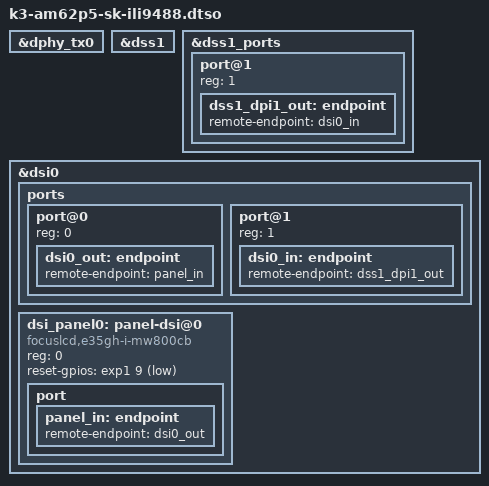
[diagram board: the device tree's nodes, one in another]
// SPDX-License-Identifier: GPL-2.0-or-later OR MIT
/**
 * Focus LCD MIPI DSI panel E35GH-I-MW800-CB
 *
 * AM62P5-SK EVM: https://www.ti.com/tool/SK-AM62P-LP
 * Panel: focuslcds.com/wp-content/uploads/2025/09/E35GH-I-MW800-CB_Spec.pdf
 *
 * Copyright (C) 2024 Texas Instruments Incorporated - http://www.ti.com/
 */

/dts-v1/;
/plugin/;

#include <dt-bindings/gpio/gpio.h>
#include <dt-bindings/interrupt-controller/irq.h>

&dphy_tx0 {
	status = "okay";
};

&dss1 {
	status = "okay";
};

&dss1_ports {
	#address-cells = <1>;
	#size-cells = <0>;

	/* DSS1-VP1: DSI Output */
	port@1 {
		reg = <1>;

		dss1_dpi1_out: endpoint {
			remote-endpoint = <&dsi0_in>;
		};
	};
};

&dsi0 {
	status = "okay";
	#address-cells = <1>;
	#size-cells = <0>;

	ports {
		#address-cells = <1>;
		#size-cells = <0>;

		port@0 {
			reg = <0>;

			dsi0_out: endpoint {
				remote-endpoint = <&panel_in>;
			};
		};

		port@1 {
			reg = <1>;

			dsi0_in: endpoint {
				remote-endpoint = <&dss1_dpi1_out>;
			};
		};
	};

	dsi_panel0: panel-dsi@0 {
		compatible = "focuslcd,e35gh-i-mw800cb", "ilitek,ili9488";
		reg = <0>;

		reset-gpios = <&exp1 9 GPIO_ACTIVE_LOW>;

		port {
			panel_in: endpoint {
				remote-endpoint = <&dsi0_out>;
			};
		};
	};
};
